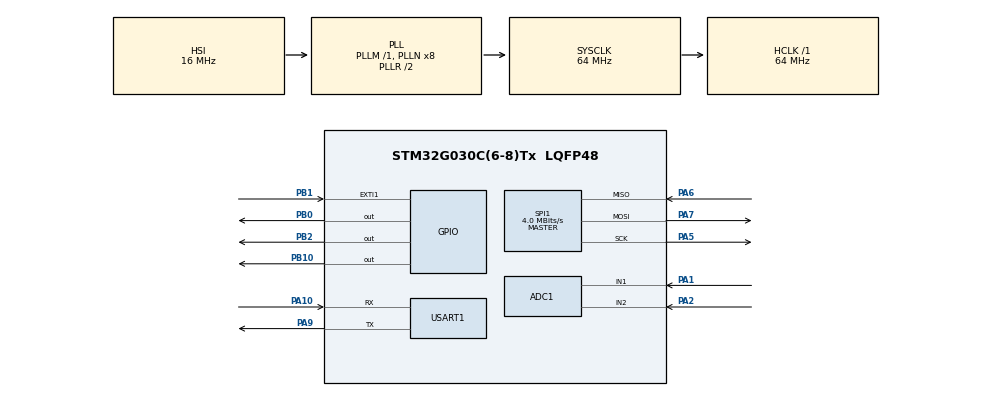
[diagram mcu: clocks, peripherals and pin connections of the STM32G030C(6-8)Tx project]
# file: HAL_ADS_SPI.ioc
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ADC1.Channel-3\#ChannelRegularConversion=ADC_CHANNEL_1
ADC1.NbrOfConversionFlag=1
ADC1.Rank-3\#ChannelRegularConversion=1
ADC1.SamplingTime-3\#ChannelRegularConversion=ADC_SAMPLINGTIME_COMMON_1
ADC1.SelectedChannel=ADC_CHANNEL_1|ADC_CHANNEL_2
ADC1.master=1
Dma.Request0=USART1_TX
Dma.USART1_TX.0.Direction=DMA_MEMORY_TO_PERIPH
Dma.USART1_TX.0.EventEnable=DISABLE
Dma.USART1_TX.0.Instance=DMA1_Channel1
Dma.USART1_TX.0.MemDataAlignment=DMA_MDATAALIGN_BYTE
Dma.USART1_TX.0.MemInc=DMA_MINC_ENABLE
Dma.USART1_TX.0.Mode=DMA_NORMAL
Dma.USART1_TX.0.PeriphDataAlignment=DMA_PDATAALIGN_BYTE
Dma.USART1_TX.0.PeriphInc=DMA_PINC_DISABLE
Dma.USART1_TX.0.Polarity=HAL_DMAMUX_REQ_GEN_RISING
Dma.USART1_TX.0.Priority=DMA_PRIORITY_LOW
Dma.USART1_TX.0.RequestNumber=1
Dma.USART1_TX.0.SignalID=NONE
Dma.USART1_TX.0.SyncEnable=DISABLE
Dma.USART1_TX.0.SyncPolarity=HAL_DMAMUX_SYNC_NO_EVENT
Dma.USART1_TX.0.SyncRequestNumber=1
Dma.USART1_TX.0.SyncSignalID=NONE
Mcu.Family=STM32G0
Mcu.Name=STM32G030C(6-8)Tx
Mcu.Package=LQFP48
NVIC.DMA1_Channel1_IRQn=true\:0\:0\:false\:false\:true\:false\:true\:true
NVIC.EXTI0_1_IRQn=true\:1\:0\:true\:false\:true\:true\:true\:true
PA1.Mode=IN1
PA1.Signal=ADC1_IN1
PA10.Mode=Asynchronous
PA10.Signal=USART1_RX
PA13.Mode=Serial_Wire
PA13.Signal=SYS_SWDIO
PA14-BOOT0.Mode=Serial_Wire
PA14-BOOT0.Signal=SYS_SWCLK
PA2.Mode=IN2
PA2.Signal=ADC1_IN2
PA5.Mode=Full_Duplex_Master
PA5.Signal=SPI1_SCK
PA6.Mode=Full_Duplex_Master
PA6.Signal=SPI1_MISO
PA7.Mode=Full_Duplex_Master
PA7.Signal=SPI1_MOSI
PA9.Mode=Asynchronous
PA9.Signal=USART1_TX
PB0.GPIO_Speed=GPIO_SPEED_FREQ_HIGH
PB0.PinState=GPIO_PIN_SET
PB0.Signal=GPIO_Output
PB1.GPIO_ModeDefaultEXTI=GPIO_MODE_IT_FALLING
PB1.Signal=GPXTI1
PB10.PinState=GPIO_PIN_SET
PB10.Signal=GPIO_Output
PB2.PinState=GPIO_PIN_RESET
PB2.Signal=GPIO_Output
PF0-OSC_IN\ (PF0).Mode=HSE-External-Clock-Source
PF0-OSC_IN\ (PF0).Signal=RCC_OSC_IN
ProjectManager.HeapSize=0x200
ProjectManager.StackSize=0x400
ProjectManager.TargetToolchain=MDK-ARM V5.32
RCC.ADCFreq_Value=64000000
RCC.AHBFreq_Value=64000000
RCC.CortexFreq_Value=64000000
RCC.EXTERNAL_CLOCK_VALUE=12288000
RCC.HCLKFreq_Value=64000000
RCC.HSE_VALUE=8000000
RCC.HSI_VALUE=16000000
RCC.LSE_VALUE=32768
RCC.SYSCLKFreq_VALUE=64000000
RCC.SYSCLKSource=RCC_SYSCLKSOURCE_PLLCLK
RCC.VCOOutputFreq_Value=128000000
SPI1.BaudRatePrescaler=SPI_BAUDRATEPRESCALER_16
SPI1.CLKPhase=SPI_PHASE_2EDGE
SPI1.CalculateBaudRate=4.0 MBits/s
SPI1.Direction=SPI_DIRECTION_2LINES
SPI1.Mode=SPI_MODE_MASTER
SPI1.VirtualType=VM_MASTER
USART1.VirtualMode-Asynchronous=VM_ASYNC
board=custom

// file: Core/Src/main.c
/* USER CODE BEGIN Header */
/**
  ******************************************************************************
  * @file           : main.c
  * @brief          : Main program body
  ******************************************************************************
  * @attention
  *
  * Copyright (c) 2026 STMicroelectronics.
  * All rights reserved.
  *
  * This software is licensed under terms that can be found in the LICENSE file
  * in the root directory of this software component.
  * If no LICENSE file comes with this software, it is provided AS-IS.
  *
  ******************************************************************************
  */
/* USER CODE END Header */
#include "main.h"
#include "adc.h"
#include "dma.h"
#include "spi.h"
#include "usart.h"
#include "gpio.h"

/* USER CODE BEGIN Includes */
#include "bsp_ads1292.h"
#include "bsp_usart_dma.h"
/* USER CODE END Includes */

/* USER CODE BEGIN PV */
volatile uint8_t g_ads1292_data_ready = 0; // 新数据就绪标志
/* USER CODE END PV */

void SystemClock_Config(void);

int main(void)
{

  /* MCU Configuration--------------------------------------------------------*/

  /* Reset of all peripherals, Initializes the Flash interface and the Systick. */
  HAL_Init();

  /* Configure the system clock */
  SystemClock_Config();

  /* Initialize all configured peripherals */
  MX_GPIO_Init();
  MX_DMA_Init();
  MX_ADC1_Init();
  MX_SPI1_Init();
  MX_USART1_UART_Init();
  /* USER CODE BEGIN 2 */
  // 初始化 ADS1292
    ADS1292_Init_Config();
  // 启动连续转换数据
    ADS1292_Start_Continuous_Conversion();
  /* USER CODE END 2 */

  /* Infinite loop */
  /* USER CODE BEGIN WHILE */
    int32_t ecg_data = 0;
    int32_t resp_data = 0;
  while (1)
  {
    /* USER CODE END WHILE */

    /* USER CODE BEGIN 3 */
    if (g_ads1292_data_ready) {
        g_ads1292_data_ready = 0;
        ADS1292_Read_ECG_Data(&ecg_data, &resp_data);
        Send_Data(ecg_data, resp_data);
    }
  }
  /* USER CODE END 3 */
}

void SystemClock_Config(void)
{
  RCC_OscInitTypeDef RCC_OscInitStruct = {0};
  RCC_ClkInitTypeDef RCC_ClkInitStruct = {0};

  /** Configure the main internal regulator output voltage
  */
  HAL_PWREx_ControlVoltageScaling(PWR_REGULATOR_VOLTAGE_SCALE1);

  /** Initializes the RCC Oscillators according to the specified parameters
  * in the RCC_OscInitTypeDef structure.
  */
  RCC_OscInitStruct.OscillatorType = RCC_OSCILLATORTYPE_HSI;
  RCC_OscInitStruct.HSIState = RCC_HSI_ON;
  RCC_OscInitStruct.HSIDiv = RCC_HSI_DIV1;
  RCC_OscInitStruct.HSICalibrationValue = RCC_HSICALIBRATION_DEFAULT;
  RCC_OscInitStruct.PLL.PLLState = RCC_PLL_ON;
  RCC_OscInitStruct.PLL.PLLSource = RCC_PLLSOURCE_HSI;
  RCC_OscInitStruct.PLL.PLLM = RCC_PLLM_DIV1;
  RCC_OscInitStruct.PLL.PLLN = 8;
  RCC_OscInitStruct.PLL.PLLP = RCC_PLLP_DIV2;
  RCC_OscInitStruct.PLL.PLLR = RCC_PLLR_DIV2;
  if (HAL_RCC_OscConfig(&RCC_OscInitStruct) != HAL_OK)
  {
    Error_Handler();
  }

  /** Initializes the CPU, AHB and APB buses clocks
  */
  RCC_ClkInitStruct.ClockType = RCC_CLOCKTYPE_HCLK|RCC_CLOCKTYPE_SYSCLK
                              |RCC_CLOCKTYPE_PCLK1;
  RCC_ClkInitStruct.SYSCLKSource = RCC_SYSCLKSOURCE_PLLCLK;
  RCC_ClkInitStruct.AHBCLKDivider = RCC_SYSCLK_DIV1;
  RCC_ClkInitStruct.APB1CLKDivider = RCC_HCLK_DIV1;

  if (HAL_RCC_ClockConfig(&RCC_ClkInitStruct, FLASH_LATENCY_2) != HAL_OK)
  {
    Error_Handler();
  }
}

/* USER CODE BEGIN 4 */
// DRDY 下降沿中断回调
void HAL_GPIO_EXTI_Callback(uint16_t GPIO_Pin) {
    if (GPIO_Pin == ADS1292_DRDY_PIN) {
        g_ads1292_data_ready = 1;
    }
}
/* USER CODE END 4 */

void Error_Handler(void)
{
  __disable_irq();
  while (1)
  {
  }
}
